# OTTOCAL_OTTOCAL_502E0000h register map
Vendor: Texas Instruments
Peripheral module from a debugger description file (folder AM263P).
Registers are 16-bit, access per field, reset 0x0 unless marked. A register's access mark holds for its fields unless they carry their own. Offsets are as the file gives them; lines under a group give offsets from that group; [hi:lo] are bit positions; {n}, {i} and the like mark numbered series; 'fields as' and 'values as' point back to an identical list; <NAME> marks a mode.

## OTTOCAL
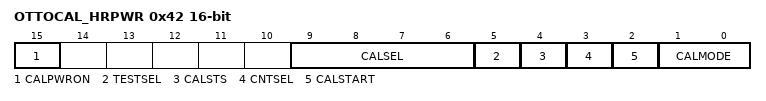
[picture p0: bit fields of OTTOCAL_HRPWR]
0x42 OTTOCAL_HRPWR — HRPWM Power Register This register is only accessible on EPWM modules with HRPWM capabilities.
  [15] CALPWRON rw — MEP Calibration Power Bits [only available on ePWM1] 0:Disables MEP calibration logic in the HRPWM and reduces power consumption. 1:Enables MEP calibration logic
  [9:6] CALSEL rw — EPWM Delay Line Selection for Calibration:
  [5] TESTSEL rw — Test Mode Select Bit: This bit selects if a dummy delay is added in Oscillator Calibration mode to help reducing frequency when small delays are used:
  [4] CALSTS ro — Calibration Status Bit: This bit, when set to 1, indicates that calibration is in progress. It is set to 0 when:
  [3] CNTSEL rw — Counter Select Bit: Functionality of this bit has changed. When HRCNT0 or HRCNT1 reaches 0xFFFF, both counters are frozen. This bit will have an effect on when calibration starts:
  [2] CALSTART rw — Calibration Start/Stop Bit:
  [1:0] CALMODE rw — Note: CALMODE bits in HRPWM Module. Not used here.
0x4C OTTOCAL_HRMSTEP rw — HRPWM MEP Step Register This register is only accessible on EPWM modules with HRPWM capabilities. Only 16 bit accesses are allowed for this register. Debugger access in 32 bit mode may display incorrect values.
  [7:0] HRMSTEP — High Resolution MEP Step When auto-conversion is enabled [HRCNFG[AUTOCONV] = 1], This 8-bit field contains the MEP_ScaleFactor [number of MEP steps per coarse steps] used by the hardware to automatically convert the value in the CMPAHR, CMPBHR, DBFEDHR, DBREDHR , TBPHSHR, or TBPRDHR register to a scaled micro-edge delay on the high-resolution ePWM output. The value in this register is written by the SFO calibration software at the end of each calibration run.
